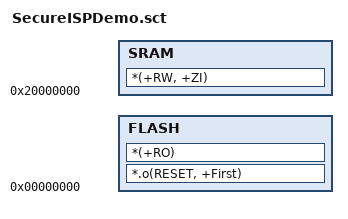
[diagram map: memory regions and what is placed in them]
FLASH 0x0
{
    FLASH   +0
    {
        *.o(RESET, +First)
        *(+RO)
    }
    
    SRAM    0x20000000
    {
        *(+RW, +ZI)
    }	
}

; Remove XO attribute in Keil v5.26.2.0 (Nuvoton Edition)
;XOM0 0x10000    ; located in 64K
;{
;    XOM0_ROM +0
;    {
;        * (+XO)
;    }    
;}
